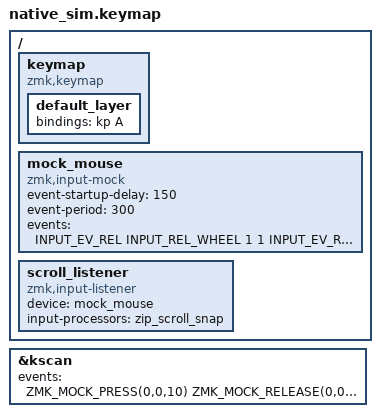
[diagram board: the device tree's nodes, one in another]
#include <dt-bindings/zmk/keys.h>
#include <behaviors.dtsi>
#include <dt-bindings/zmk/kscan_mock.h>
#include <scroll-snap.dtsi>

/ {
    keymap {
        compatible = "zmk,keymap";

        default_layer {
            bindings = <&kp A>;
        };
    };

    mock_mouse: mock_mouse {
        compatible = "zmk,input-mock";
        event-startup-delay = <150>;
        event-period = <300>;
        events = <
            INPUT_EV_REL INPUT_REL_WHEEL 1 1
            INPUT_EV_REL INPUT_REL_HWHEEL 1 1
            INPUT_EV_REL INPUT_REL_X 10 1
            INPUT_EV_REL INPUT_REL_Y 10 1
        >;
    };

    scroll_listener: scroll_listener {
        compatible = "zmk,input-listener";
        device = <&mock_mouse>;
        input-processors = <&zip_scroll_snap>;
    };
};

&kscan {
    events = <
        ZMK_MOCK_PRESS(0,0,10)
        ZMK_MOCK_RELEASE(0,0,10)
    >;
};
